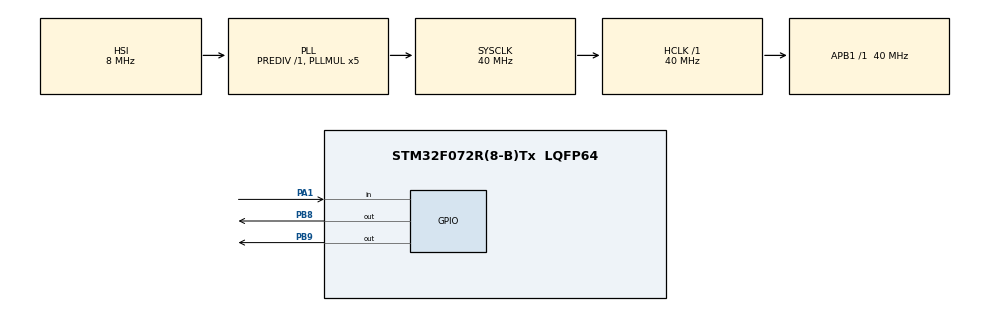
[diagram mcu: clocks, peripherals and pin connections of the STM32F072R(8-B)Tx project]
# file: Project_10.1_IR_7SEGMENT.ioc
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Mcu.Family=STM32F0
Mcu.Name=STM32F072R(8-B)Tx
Mcu.Package=LQFP64
PA1.Signal=GPIO_Input
PB8.GPIO_ModeDefaultOutputPP=GPIO_MODE_OUTPUT_OD
PB8.GPIO_PuPd=GPIO_NOPULL
PB8.GPIO_Speed=GPIO_SPEED_FREQ_MEDIUM
PB8.PinState=GPIO_PIN_SET
PB8.Signal=GPIO_Output
PB9.GPIO_ModeDefaultOutputPP=GPIO_MODE_OUTPUT_OD
PB9.GPIO_PuPd=GPIO_NOPULL
PB9.GPIO_Speed=GPIO_SPEED_FREQ_MEDIUM
PB9.PinState=GPIO_PIN_SET
PB9.Signal=GPIO_Output
PF0-OSC_IN.Mode=HSE-External-Oscillator
PF0-OSC_IN.Signal=RCC_OSC_IN
PF1-OSC_OUT.Mode=HSE-External-Oscillator
PF1-OSC_OUT.Signal=RCC_OSC_OUT
ProjectManager.HeapSize=0x200
ProjectManager.StackSize=0x400
ProjectManager.TargetToolchain=STM32CubeIDE
RCC.AHBFreq_Value=40000000
RCC.APB1Freq_Value=40000000
RCC.APB1TimFreq_Value=40000000
RCC.HCLKFreq_Value=40000000
RCC.PLLMUL=RCC_PLL_MUL5
RCC.SYSCLKFreq_VALUE=40000000
RCC.SYSCLKSource=RCC_SYSCLKSOURCE_PLLCLK
TIM2.AutoReloadPreload=TIM_AUTORELOAD_PRELOAD_ENABLE
TIM2.Period=65535
TIM2.Prescaler=39
VP_TIM2_VS_ClockSourceINT.Mode=Internal
board=custom

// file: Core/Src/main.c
/* USER CODE BEGIN Header */
/**
  ******************************************************************************
  * @file           : main.c
  * @brief          : Main program body
  ******************************************************************************
  * @attention
  *
  * Copyright (c) 2023 STMicroelectronics.
  * All rights reserved.
  *
  * This software is licensed under terms that can be found in the LICENSE file
  * in the root directory of this software component.
  * If no LICENSE file comes with this software, it is provided AS-IS.
  *
  ******************************************************************************
  */
/* USER CODE END Header */
#include "main.h"

/* USER CODE BEGIN Includes */
#include "dwt.h"
#include "ir_lib.h"
#include "TM1637.h"
/* USER CODE END Includes */

void SystemClock_Config(void);
static void MX_GPIO_Init(void);

/* USER CODE BEGIN 0 */
uint32_t r_data;
uint32_t number;

uint32_t arr[5];
uint8_t countt=0;
/* USER CODE END 0 */

int main(void)
{

  /* MCU Configuration--------------------------------------------------------*/

  /* Reset of all peripherals, Initializes the Flash interface and the Systick. */
  HAL_Init();

  /* Configure the system clock */
  SystemClock_Config();

  /* Initialize all configured peripherals */
  MX_GPIO_Init();
  MX_TIM2_Init();
  /* USER CODE BEGIN 2 */
  Display_Init(8);
  /* USER CODE END 2 */

  /* Infinite loop */
  /* USER CODE BEGIN WHILE */
  while (1)
  {
		while (HAL_GPIO_ReadPin(GPIOA, GPIO_PIN_1))
			;   // wait for the pin to go low

		r_data = receive_data();

		number = convert_code(r_data);
		HAL_Delay(200);

		arr[0] = tm1637_NumberToSegments(number);

		countt++;

		if (countt == 4)
			countt = 0;

		sendTo_Display(arr[3], arr[2], arr[1], arr[0]);

		for (int i = 3; i > 0; i--) {
			arr[i] = arr[i - 1];
		}
    /* USER CODE END WHILE */

  }
}

void SystemClock_Config(void)
{
  RCC_OscInitTypeDef RCC_OscInitStruct = {0};
  RCC_ClkInitTypeDef RCC_ClkInitStruct = {0};

  /** Initializes the RCC Oscillators according to the specified parameters
  * in the RCC_OscInitTypeDef structure.
  */
  RCC_OscInitStruct.OscillatorType = RCC_OSCILLATORTYPE_HSI;
  RCC_OscInitStruct.HSIState = RCC_HSI_ON;
  RCC_OscInitStruct.HSICalibrationValue = RCC_HSICALIBRATION_DEFAULT;
  RCC_OscInitStruct.PLL.PLLState = RCC_PLL_ON;
  RCC_OscInitStruct.PLL.PLLSource = RCC_PLLSOURCE_HSI;
  RCC_OscInitStruct.PLL.PLLMUL = RCC_PLL_MUL5;
  RCC_OscInitStruct.PLL.PREDIV = RCC_PREDIV_DIV1;
  if (HAL_RCC_OscConfig(&RCC_OscInitStruct) != HAL_OK)
  {
    Error_Handler();
  }

  /** Initializes the CPU, AHB and APB buses clocks
  */
  RCC_ClkInitStruct.ClockType = RCC_CLOCKTYPE_HCLK|RCC_CLOCKTYPE_SYSCLK
                              |RCC_CLOCKTYPE_PCLK1;
  RCC_ClkInitStruct.SYSCLKSource = RCC_SYSCLKSOURCE_PLLCLK;
  RCC_ClkInitStruct.AHBCLKDivider = RCC_SYSCLK_DIV1;
  RCC_ClkInitStruct.APB1CLKDivider = RCC_HCLK_DIV1;

  if (HAL_RCC_ClockConfig(&RCC_ClkInitStruct, FLASH_LATENCY_1) != HAL_OK)
  {
    Error_Handler();
  }
}

static void MX_GPIO_Init(void)
{
  GPIO_InitTypeDef GPIO_InitStruct = {0};

  /* GPIO Ports Clock Enable */
  __HAL_RCC_GPIOF_CLK_ENABLE();
  __HAL_RCC_GPIOA_CLK_ENABLE();
  __HAL_RCC_GPIOB_CLK_ENABLE();

  /*Configure GPIO pin Output Level */
  HAL_GPIO_WritePin(GPIOB, GPIO_PIN_8|GPIO_PIN_9, GPIO_PIN_SET);

  /*Configure GPIO pin : PA1 */
  GPIO_InitStruct.Pin = GPIO_PIN_1;
  GPIO_InitStruct.Mode = GPIO_MODE_INPUT;
  GPIO_InitStruct.Pull = GPIO_NOPULL;
  HAL_GPIO_Init(GPIOA, &GPIO_InitStruct);

  /*Configure GPIO pins : PB8 PB9 */
  GPIO_InitStruct.Pin = GPIO_PIN_8|GPIO_PIN_9;
  GPIO_InitStruct.Mode = GPIO_MODE_OUTPUT_OD;
  GPIO_InitStruct.Pull = GPIO_NOPULL;
  GPIO_InitStruct.Speed = GPIO_SPEED_FREQ_MEDIUM;
  HAL_GPIO_Init(GPIOB, &GPIO_InitStruct);

}

void Error_Handler(void)
{
  __disable_irq();
  while (1)
  {
  }
}
